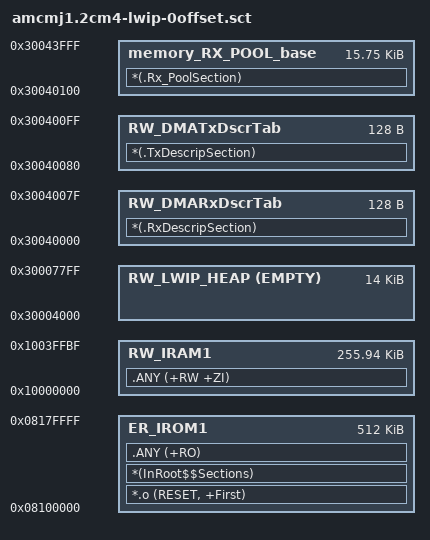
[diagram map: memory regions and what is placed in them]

; this scatter file is for a single application on CM7. it uses following FLASH and RAM resources:
;
; - FLASH: first bank @ 0x08000000 for a size of 512k
; 
; - RAM: AXI SRAM @ 0x24000000 for a size of 512K
;
; - NOTES:
;   1.  the maximum amount of flash is 1024k (0x100000) and one can decide to place the code in any position in its inside
;       For instance:
;       - on the core that uses eth, the loader starts at +000k (+0x00000), the updater at +128k (+0x20000) and the the appl.yri at +384k (0x60000) 
;       - on the other core the appl.mot starts at +000k
;   2. we must keep a RAM hole @ 0x1003FFC0 of size 64B for the core that uses IPC. 
;      This hole is on top of SRAM1-SRAM2 used by the CM4
;   3. The core that uses the ethernet must also specify that some modules are in dedicated RAM parts. See commented section
;

LR_IROM1 0x08100000 0x00080000  {    ; load region size_region
  
  ; flash
  ER_IROM1 0x08100000 0x00080000  {  ; load address = execution address
   *.o (RESET, +First)
   *(InRoot$$Sections)
   .ANY (+RO)
  }
  
  ; banks sram1 and sram2 joined together with a 64 bytes hole on top for ipc
  RW_IRAM1 0x10000000 0x0003FFC0 {
   .ANY (+RW +ZI)
  }
  


; ram for lwip heap - SRAM1 @ 0x30004000
; 0x3800 = 14*1024 = the lwip.MEM_SIZE, 0x30004000 = LWIP_RAM_HEAP_POINTER
  RW_LWIP_HEAP 0x30004000 EMPTY 0x3800  {
  }

; w/ 0x80 = 128 i can have up to 5 ETH_DMADescTypeDef, so check that ETH_TX_DESC_CNT and ETH_RX_DESC_CNT are <=5. 
  RW_DMARxDscrTab 0x30040000 0x80 {
  *(.RxDescripSection)
  }
  RW_DMATxDscrTab 0x30040080 0x80 {
  *(.TxDescripSection)
  }
  
; w/ 0x3F00 (16128 byte) i can accomodate ETH_RX_BUFFER_CNT * sizeof(RxBuff_t) = 8 в 1572 = 12576 byte (0x3120)
  memory_RX_POOL_base 0x30040100 0x3F00 {
  *(.Rx_PoolSection)
  }
}
